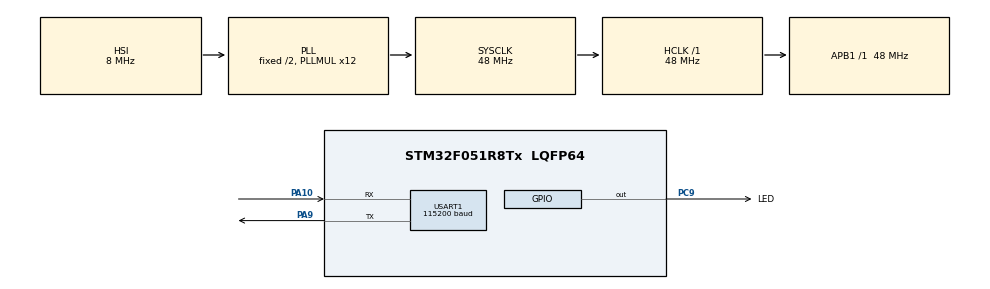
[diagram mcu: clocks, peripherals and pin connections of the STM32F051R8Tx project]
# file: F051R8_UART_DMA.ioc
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Mcu.Family=STM32F0
Dma.USART1_TX.1.Instance=DMA1_Channel2
Dma.USART1_RX.0.PeriphDataAlignment=DMA_PDATAALIGN_BYTE
PA10.Mode=Asynchronous
Dma.USART1_TX.1.MemInc=DMA_MINC_ENABLE
PC9.GPIO_Label=LED
USART1.BaudRate=115200
PA14.GPIO_Label=SWCLK
RCC.SYSCLKSource=RCC_SYSCLKSOURCE_PLLCLK
ProjectManager.StackSize=0x400
USART1.VirtualMode-Asynchronous=VM_ASYNC
PA13.Signal=SYS_SWDIO
PA9.Mode=Asynchronous
ProjectManager.TargetToolchain=STM32CubeIDE
Dma.USART1_RX.0.Direction=DMA_PERIPH_TO_MEMORY
RCC.HCLKFreq_Value=48000000
PA9.Signal=USART1_TX
RCC.AHBFreq_Value=48000000
Dma.USART1_RX.0.PeriphInc=DMA_PINC_DISABLE
Dma.USART1_RX.0.Priority=DMA_PRIORITY_LOW
Dma.USART1_TX.1.MemDataAlignment=DMA_MDATAALIGN_BYTE
board=STM32F0DISCOVERY
RCC.PLLMUL=RCC_PLL_MUL12
PA14.Mode=Serial_Wire
Dma.USART1_RX.0.MemDataAlignment=DMA_MDATAALIGN_BYTE
Dma.USART1_RX.0.MemInc=DMA_MINC_ENABLE
PA13.Mode=Serial_Wire
Mcu.Name=STM32F051R8Tx
Dma.USART1_TX.1.PeriphDataAlignment=DMA_PDATAALIGN_BYTE
PA13.GPIO_Label=SWDIO
RCC.SYSCLKFreq_VALUE=48000000
Mcu.Package=LQFP64
Dma.USART1_TX.1.Mode=DMA_NORMAL
PA10.Signal=USART1_RX
PA14.Signal=SYS_SWCLK
ProjectManager.HeapSize=0x200
Dma.USART1_TX.1.PeriphInc=DMA_PINC_DISABLE
NVIC.DMA1_Channel2_3_IRQn=true\:0\:0\:false\:false\:true\:false\:true
Dma.Request1=USART1_TX
RCC.APB1TimFreq_Value=48000000
Dma.USART1_RX.0.Mode=DMA_CIRCULAR
Dma.USART1_TX.1.Priority=DMA_PRIORITY_LOW
PC9.Signal=GPIO_Output
NVIC.USART1_IRQn=true\:0\:0\:false\:false\:true\:true\:true
Dma.Request0=USART1_RX
RCC.APB1Freq_Value=48000000
Dma.USART1_RX.0.Instance=DMA1_Channel3
Dma.USART1_TX.1.Direction=DMA_MEMORY_TO_PERIPH

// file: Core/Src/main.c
/* USER CODE BEGIN Header */
/**
 ******************************************************************************
 * @file           : main.c
 * @brief          : Main program body
 ******************************************************************************
 * @attention
 *
 * <h2><center>&copy; Copyright (c) 2021 STMicroelectronics.
 * All rights reserved.</center></h2>
 *
 * This software component is licensed by ST under BSD 3-Clause license,
 * the "License"; You may not use this file except in compliance with the
 * License. You may obtain a copy of the License at:
 *                        opensource.org/licenses/BSD-3-Clause
 *
 ******************************************************************************
 */
/* USER CODE END Header */
#include "main.h"

/* USER CODE BEGIN Includes */
#include <stdio.h>
#include <string.h>
/* USER CODE END Includes */

UART_HandleTypeDef huart1;
DMA_HandleTypeDef hdma_usart1_rx;
DMA_HandleTypeDef hdma_usart1_tx;

/* USER CODE BEGIN PV */
char counter = 0;

#define DMA_BUFFER_MAX 16
char tx_buffer[DMA_BUFFER_MAX] = { 0 };
char rx_buffer[DMA_BUFFER_MAX] = { 0 };

#define UART_BUFFER_MAX   64
char uart_buffer[UART_BUFFER_MAX] = { 0 };
size_t uart_buffer_idx = 0;
char uart_new_string = 0;

const char MSG_PAUSE[] = "PAUSED\n\r";
const char MSG_RESUME[] = "RESUMED\n\r";
/* USER CODE END PV */

void SystemClock_Config(void);
static void MX_GPIO_Init(void);
static void MX_DMA_Init(void);
static void MX_USART1_UART_Init(void);

/* USER CODE BEGIN 0 */
HAL_StatusTypeDef Write(const char *buffer) {
  while (HAL_UART_Transmit_DMA(&huart1, (uint8_t*) buffer, strlen(buffer)) != HAL_OK);
  return HAL_OK;
}

void UART_RX_Process(const void *data, size_t len) {
  for (int i = 0; i < len; i++) {
    char c = ((char*) data)[i];
    if (uart_buffer_idx < UART_BUFFER_MAX-2) {
      uart_buffer[uart_buffer_idx++] = c;
      uart_buffer[uart_buffer_idx] = '\0';
    }
    if (c == '\n') {
      uart_buffer_idx = 0;
      uart_new_string = 1;
    }
  }
}

void UART_RX_Check(DMA_HandleTypeDef *hdma) {
  static size_t old_pos = 0;
  size_t rx_pos = DMA_BUFFER_MAX - hdma->Instance->CNDTR;
  if (rx_pos != old_pos) { // new data
    if (rx_pos > old_pos) { // no overflow
      UART_RX_Process(&rx_buffer[old_pos], rx_pos - old_pos);
    } else { // overflow
      UART_RX_Process(&rx_buffer[old_pos], DMA_BUFFER_MAX - old_pos);
      if (rx_pos > 0) { // run up
        UART_RX_Process(&rx_buffer[old_pos], rx_pos);
      }
    }
    old_pos = rx_pos;
  }
}

void HAL_UART_RxCpltCallback(UART_HandleTypeDef *huart) {
  UART_RX_Check(&hdma_usart1_rx);
}

void HAL_UART_RxHalfCpltCallback(UART_HandleTypeDef *huart) {
  UART_RX_Check(&hdma_usart1_rx);
}
/* USER CODE END 0 */

int main(void) {
  /* USER CODE BEGIN 1 */
  char pause = 0;
  /* USER CODE END 1 */

  /* MCU Configuration--------------------------------------------------------*/

  /* Reset of all peripherals, Initializes the Flash interface and the Systick. */
  HAL_Init();

  /* Configure the system clock */
  SystemClock_Config();

  /* Initialize all configured peripherals */
  MX_GPIO_Init();
  MX_DMA_Init();
  MX_USART1_UART_Init();
  /* USER CODE BEGIN 2 */
  __HAL_UART_ENABLE_IT(&huart1, UART_IT_IDLE);
  /* USER CODE END 2 */

  /* Infinite loop */
  /* USER CODE BEGIN WHILE */
  HAL_UART_Receive_DMA(&huart1, (uint8_t*)rx_buffer, DMA_BUFFER_MAX);
  while (1) {
    if (pause == 0) {
      counter++;
      sprintf(tx_buffer, "counter=%03d\n\r", counter);
      Write(tx_buffer);
    }

    if (uart_new_string == 1) {
      uart_new_string = 0;
      if (strncmp(uart_buffer, "stop", 4) == 0) {
        pause = 1;
        Write(MSG_PAUSE);
      } else if(strncmp(uart_buffer, "resume", 6) == 0) {
        pause = 0;
        Write(MSG_RESUME);
      }
    }
    HAL_GPIO_TogglePin(LED_GPIO_Port, LED_Pin);
    HAL_Delay(1000);
    /* USER CODE END WHILE */

  }
}

void SystemClock_Config(void) {
  RCC_OscInitTypeDef RCC_OscInitStruct = { 0 };
  RCC_ClkInitTypeDef RCC_ClkInitStruct = { 0 };
  RCC_PeriphCLKInitTypeDef PeriphClkInit = { 0 };

  /** Initializes the RCC Oscillators according to the specified parameters
   * in the RCC_OscInitTypeDef structure.
   */
  RCC_OscInitStruct.OscillatorType = RCC_OSCILLATORTYPE_HSI;
  RCC_OscInitStruct.HSIState = RCC_HSI_ON;
  RCC_OscInitStruct.HSICalibrationValue = RCC_HSICALIBRATION_DEFAULT;
  RCC_OscInitStruct.PLL.PLLState = RCC_PLL_ON;
  RCC_OscInitStruct.PLL.PLLSource = RCC_PLLSOURCE_HSI;
  RCC_OscInitStruct.PLL.PLLMUL = RCC_PLL_MUL12;
  RCC_OscInitStruct.PLL.PREDIV = RCC_PREDIV_DIV1;
  if (HAL_RCC_OscConfig(&RCC_OscInitStruct) != HAL_OK) {
    Error_Handler();
  }
  /** Initializes the CPU, AHB and APB buses clocks
   */
  RCC_ClkInitStruct.ClockType = RCC_CLOCKTYPE_HCLK | RCC_CLOCKTYPE_SYSCLK
      | RCC_CLOCKTYPE_PCLK1;
  RCC_ClkInitStruct.SYSCLKSource = RCC_SYSCLKSOURCE_PLLCLK;
  RCC_ClkInitStruct.AHBCLKDivider = RCC_SYSCLK_DIV1;
  RCC_ClkInitStruct.APB1CLKDivider = RCC_HCLK_DIV1;

  if (HAL_RCC_ClockConfig(&RCC_ClkInitStruct, FLASH_LATENCY_1) != HAL_OK) {
    Error_Handler();
  }
  PeriphClkInit.PeriphClockSelection = RCC_PERIPHCLK_USART1;
  PeriphClkInit.Usart1ClockSelection = RCC_USART1CLKSOURCE_PCLK1;
  if (HAL_RCCEx_PeriphCLKConfig(&PeriphClkInit) != HAL_OK) {
    Error_Handler();
  }
}

static void MX_USART1_UART_Init(void) {

  huart1.Instance = USART1;
  huart1.Init.BaudRate = 115200;
  huart1.Init.WordLength = UART_WORDLENGTH_8B;
  huart1.Init.StopBits = UART_STOPBITS_1;
  huart1.Init.Parity = UART_PARITY_NONE;
  huart1.Init.Mode = UART_MODE_TX_RX;
  huart1.Init.HwFlowCtl = UART_HWCONTROL_NONE;
  huart1.Init.OverSampling = UART_OVERSAMPLING_16;
  huart1.Init.OneBitSampling = UART_ONE_BIT_SAMPLE_DISABLE;
  huart1.AdvancedInit.AdvFeatureInit = UART_ADVFEATURE_NO_INIT;
  if (HAL_UART_Init(&huart1) != HAL_OK) {
    Error_Handler();
  }

}

static void MX_DMA_Init(void) {

  /* DMA controller clock enable */
  __HAL_RCC_DMA1_CLK_ENABLE();

  /* DMA interrupt init */
  /* DMA1_Channel2_3_IRQn interrupt configuration */
  HAL_NVIC_SetPriority(DMA1_Channel2_3_IRQn, 0, 0);
  HAL_NVIC_EnableIRQ(DMA1_Channel2_3_IRQn);

}

static void MX_GPIO_Init(void) {
  GPIO_InitTypeDef GPIO_InitStruct = { 0 };

  /* GPIO Ports Clock Enable */
  __HAL_RCC_GPIOC_CLK_ENABLE();
  __HAL_RCC_GPIOA_CLK_ENABLE();

  /*Configure GPIO pin Output Level */
  HAL_GPIO_WritePin(LED_GPIO_Port, LED_Pin, GPIO_PIN_RESET);

  /*Configure GPIO pin : LED_Pin */
  GPIO_InitStruct.Pin = LED_Pin;
  GPIO_InitStruct.Mode = GPIO_MODE_OUTPUT_PP;
  GPIO_InitStruct.Pull = GPIO_NOPULL;
  GPIO_InitStruct.Speed = GPIO_SPEED_FREQ_LOW;
  HAL_GPIO_Init(LED_GPIO_Port, &GPIO_InitStruct);

}

void Error_Handler(void) {
  __disable_irq();
  while (1) {
  }
}

/************************ (C) COPYRIGHT STMicroelectronics *****END OF FILE****/
